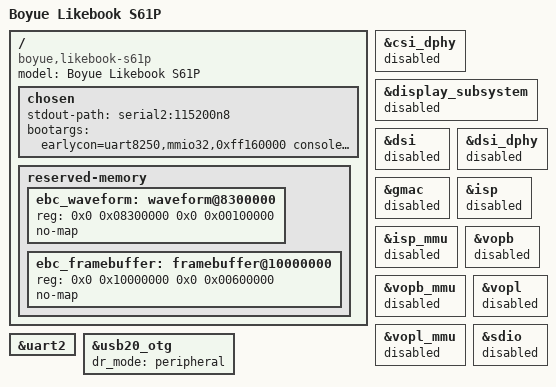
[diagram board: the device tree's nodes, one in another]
// SPDX-License-Identifier: GPL-2.0+
/*
 * Boyue Likebook S61P (Rockchip PX30, RK809 PMIC, 6" ED060XCD e-ink) - WORK IN PROGRESS
 * The stock board is a PX30 EVB derivative (rockchip,px30-evb-ddr3-v10-eink), so we reuse the
 * mainline EVB description for PMIC rails/eMMC and switch off everything this device lacks.
 * Milestone 1: boot to console (UART2) + USB gadget network. No display yet.
 */
#include "px30-evb.dts"

/ {
	model = "Boyue Likebook S61P";
	compatible = "boyue,likebook-s61p", "rockchip,px30";

	chosen {
		stdout-path = "serial2:115200n8";
		bootargs = "earlycon=uart8250,mmio32,0xff160000 console=ttyS2,115200n8 rdinit=/init";
	};

	/* Stock firmware reserves these for the e-ink engine; keep them away from Linux. */
	reserved-memory {
		#address-cells = <2>;
		#size-cells = <2>;
		ranges;

		ebc_waveform: waveform@8300000 {
			reg = <0x0 0x08300000 0x0 0x00100000>;
			no-map;
		};

		ebc_framebuffer: framebuffer@10000000 {
			reg = <0x0 0x10000000 0x0 0x00600000>;
			no-map;
		};
	};
};

/* No LCD, camera, ethernet on this board. */
&csi_dphy { status = "disabled"; };
&display_subsystem { status = "disabled"; };
&dsi { status = "disabled"; };
&dsi_dphy { status = "disabled"; };
&gmac { status = "disabled"; };
&isp { status = "disabled"; };
&isp_mmu { status = "disabled"; };
&vopb { status = "disabled"; };
&vopb_mmu { status = "disabled"; };
&vopl { status = "disabled"; };
&vopl_mmu { status = "disabled"; };
&sdio { status = "disabled"; };

&uart2 {
	status = "okay";
};

&usb20_otg {
	dr_mode = "peripheral";
	status = "okay";
};
